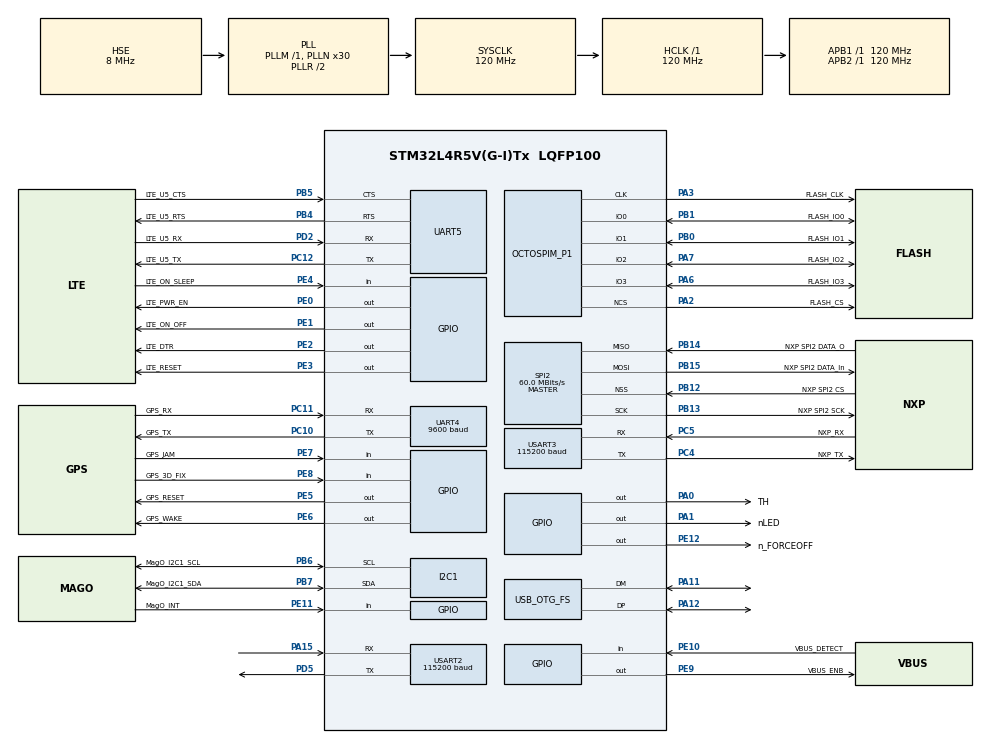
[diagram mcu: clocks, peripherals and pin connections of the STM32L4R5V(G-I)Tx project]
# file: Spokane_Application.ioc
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Dma.OCTOSPI1.10.Direction=DMA_PERIPH_TO_MEMORY
Dma.OCTOSPI1.10.EventEnable=DISABLE
Dma.OCTOSPI1.10.Instance=DMA2_Channel4
Dma.OCTOSPI1.10.MemDataAlignment=DMA_MDATAALIGN_BYTE
Dma.OCTOSPI1.10.MemInc=DMA_MINC_ENABLE
Dma.OCTOSPI1.10.Mode=DMA_NORMAL
Dma.OCTOSPI1.10.PeriphDataAlignment=DMA_PDATAALIGN_BYTE
Dma.OCTOSPI1.10.PeriphInc=DMA_PINC_DISABLE
Dma.OCTOSPI1.10.Polarity=HAL_DMAMUX_REQUEST_GEN_RISING
Dma.OCTOSPI1.10.Priority=DMA_PRIORITY_LOW
Dma.OCTOSPI1.10.RequestNumber=1
Dma.OCTOSPI1.10.SignalID=NONE
Dma.OCTOSPI1.10.SyncEnable=DISABLE
Dma.OCTOSPI1.10.SyncPolarity=HAL_DMAMUX_SYNC_NO_EVENT
Dma.OCTOSPI1.10.SyncRequestNumber=1
Dma.OCTOSPI1.10.SyncSignalID=NONE
Dma.Request0=SPI2_RX
Dma.Request1=SPI2_TX
Dma.Request10=OCTOSPI1
Dma.Request2=UART5_RX
Dma.Request3=UART5_TX
Dma.Request4=USART3_RX
Dma.Request5=USART3_TX
Dma.Request6=USART2_TX
Dma.Request7=USART2_RX
Dma.Request8=UART4_TX
Dma.Request9=UART4_RX
Dma.SPI2_RX.0.Direction=DMA_PERIPH_TO_MEMORY
Dma.SPI2_RX.0.EventEnable=DISABLE
Dma.SPI2_RX.0.Instance=DMA1_Channel5
Dma.SPI2_RX.0.MemDataAlignment=DMA_MDATAALIGN_BYTE
Dma.SPI2_RX.0.MemInc=DMA_MINC_ENABLE
Dma.SPI2_RX.0.Mode=DMA_CIRCULAR
Dma.SPI2_RX.0.PeriphDataAlignment=DMA_PDATAALIGN_BYTE
Dma.SPI2_RX.0.PeriphInc=DMA_PINC_DISABLE
Dma.SPI2_RX.0.Polarity=HAL_DMAMUX_REQUEST_GEN_RISING
Dma.SPI2_RX.0.Priority=DMA_PRIORITY_VERY_HIGH
Dma.SPI2_RX.0.RequestNumber=1
Dma.SPI2_RX.0.SignalID=NONE
Dma.SPI2_RX.0.SyncEnable=DISABLE
Dma.SPI2_RX.0.SyncPolarity=HAL_DMAMUX_SYNC_NO_EVENT
Dma.SPI2_RX.0.SyncRequestNumber=1
Dma.SPI2_RX.0.SyncSignalID=NONE
Dma.SPI2_TX.1.Direction=DMA_MEMORY_TO_PERIPH
Dma.SPI2_TX.1.EventEnable=DISABLE
Dma.SPI2_TX.1.Instance=DMA1_Channel6
Dma.SPI2_TX.1.MemDataAlignment=DMA_MDATAALIGN_BYTE
Dma.SPI2_TX.1.MemInc=DMA_MINC_ENABLE
Dma.SPI2_TX.1.Mode=DMA_NORMAL
Dma.SPI2_TX.1.PeriphDataAlignment=DMA_PDATAALIGN_BYTE
Dma.SPI2_TX.1.PeriphInc=DMA_PINC_DISABLE
Dma.SPI2_TX.1.Polarity=HAL_DMAMUX_REQUEST_GEN_RISING
Dma.SPI2_TX.1.Priority=DMA_PRIORITY_VERY_HIGH
Dma.SPI2_TX.1.RequestNumber=1
Dma.SPI2_TX.1.SignalID=NONE
Dma.SPI2_TX.1.SyncEnable=DISABLE
Dma.SPI2_TX.1.SyncPolarity=HAL_DMAMUX_SYNC_NO_EVENT
Dma.SPI2_TX.1.SyncRequestNumber=1
Dma.SPI2_TX.1.SyncSignalID=NONE
Dma.UART4_RX.9.Direction=DMA_PERIPH_TO_MEMORY
Dma.UART4_RX.9.EventEnable=DISABLE
Dma.UART4_RX.9.Instance=DMA2_Channel3
Dma.UART4_RX.9.MemDataAlignment=DMA_MDATAALIGN_BYTE
Dma.UART4_RX.9.MemInc=DMA_MINC_ENABLE
Dma.UART4_RX.9.Mode=DMA_CIRCULAR
Dma.UART4_RX.9.PeriphDataAlignment=DMA_PDATAALIGN_BYTE
Dma.UART4_RX.9.PeriphInc=DMA_PINC_DISABLE
Dma.UART4_RX.9.Polarity=HAL_DMAMUX_REQUEST_GEN_RISING
Dma.UART4_RX.9.Priority=DMA_PRIORITY_LOW
Dma.UART4_RX.9.RequestNumber=1
Dma.UART4_RX.9.SignalID=NONE
Dma.UART4_RX.9.SyncEnable=DISABLE
Dma.UART4_RX.9.SyncPolarity=HAL_DMAMUX_SYNC_NO_EVENT
Dma.UART4_RX.9.SyncRequestNumber=1
Dma.UART4_RX.9.SyncSignalID=NONE
Dma.UART4_TX.8.Direction=DMA_MEMORY_TO_PERIPH
Dma.UART4_TX.8.EventEnable=DISABLE
Dma.UART4_TX.8.Instance=DMA2_Channel2
Dma.UART4_TX.8.MemDataAlignment=DMA_MDATAALIGN_BYTE
Dma.UART4_TX.8.MemInc=DMA_MINC_ENABLE
Dma.UART4_TX.8.Mode=DMA_NORMAL
Dma.UART4_TX.8.PeriphDataAlignment=DMA_PDATAALIGN_BYTE
Dma.UART4_TX.8.PeriphInc=DMA_PINC_DISABLE
Dma.UART4_TX.8.Polarity=HAL_DMAMUX_REQUEST_GEN_RISING
Dma.UART4_TX.8.Priority=DMA_PRIORITY_LOW
Dma.UART4_TX.8.RequestNumber=1
Dma.UART4_TX.8.SignalID=NONE
Dma.UART4_TX.8.SyncEnable=DISABLE
Dma.UART4_TX.8.SyncPolarity=HAL_DMAMUX_SYNC_NO_EVENT
Dma.UART4_TX.8.SyncRequestNumber=1
Dma.UART4_TX.8.SyncSignalID=NONE
Dma.UART5_RX.2.Direction=DMA_PERIPH_TO_MEMORY
Dma.UART5_RX.2.EventEnable=DISABLE
Dma.UART5_RX.2.Instance=DMA1_Channel1
Dma.UART5_RX.2.MemDataAlignment=DMA_MDATAALIGN_BYTE
Dma.UART5_RX.2.MemInc=DMA_MINC_ENABLE
Dma.UART5_RX.2.Mode=DMA_CIRCULAR
Dma.UART5_RX.2.PeriphDataAlignment=DMA_PDATAALIGN_BYTE
Dma.UART5_RX.2.PeriphInc=DMA_PINC_DISABLE
Dma.UART5_RX.2.Polarity=HAL_DMAMUX_REQUEST_GEN_RISING
Dma.UART5_RX.2.Priority=DMA_PRIORITY_LOW
Dma.UART5_RX.2.RequestNumber=1
Dma.UART5_RX.2.SignalID=NONE
Dma.UART5_RX.2.SyncEnable=DISABLE
Dma.UART5_RX.2.SyncPolarity=HAL_DMAMUX_SYNC_NO_EVENT
Dma.UART5_RX.2.SyncRequestNumber=1
Dma.UART5_RX.2.SyncSignalID=NONE
Dma.UART5_TX.3.Direction=DMA_MEMORY_TO_PERIPH
Dma.UART5_TX.3.EventEnable=DISABLE
Dma.UART5_TX.3.Instance=DMA1_Channel2
Dma.UART5_TX.3.MemDataAlignment=DMA_MDATAALIGN_BYTE
Dma.UART5_TX.3.MemInc=DMA_MINC_ENABLE
Dma.UART5_TX.3.Mode=DMA_NORMAL
Dma.UART5_TX.3.PeriphDataAlignment=DMA_PDATAALIGN_BYTE
Dma.UART5_TX.3.PeriphInc=DMA_PINC_DISABLE
Dma.UART5_TX.3.Polarity=HAL_DMAMUX_REQUEST_GEN_RISING
Dma.UART5_TX.3.Priority=DMA_PRIORITY_LOW
Dma.UART5_TX.3.RequestNumber=1
Dma.UART5_TX.3.SignalID=NONE
Dma.UART5_TX.3.SyncEnable=DISABLE
Dma.UART5_TX.3.SyncPolarity=HAL_DMAMUX_SYNC_NO_EVENT
Dma.UART5_TX.3.SyncRequestNumber=1
Dma.UART5_TX.3.SyncSignalID=NONE
Dma.USART2_RX.7.Direction=DMA_PERIPH_TO_MEMORY
Dma.USART2_RX.7.EventEnable=DISABLE
Dma.USART2_RX.7.Instance=DMA2_Channel1
Dma.USART2_RX.7.MemDataAlignment=DMA_MDATAALIGN_BYTE
Dma.USART2_RX.7.MemInc=DMA_MINC_ENABLE
Dma.USART2_RX.7.Mode=DMA_CIRCULAR
Dma.USART2_RX.7.PeriphDataAlignment=DMA_PDATAALIGN_BYTE
Dma.USART2_RX.7.PeriphInc=DMA_PINC_DISABLE
Dma.USART2_RX.7.Polarity=HAL_DMAMUX_REQUEST_GEN_RISING
Dma.USART2_RX.7.Priority=DMA_PRIORITY_LOW
Dma.USART2_RX.7.RequestNumber=1
Dma.USART2_RX.7.SignalID=NONE
Dma.USART2_RX.7.SyncEnable=DISABLE
Dma.USART2_RX.7.SyncPolarity=HAL_DMAMUX_SYNC_NO_EVENT
Dma.USART2_RX.7.SyncRequestNumber=1
Dma.USART2_RX.7.SyncSignalID=NONE
Dma.USART2_TX.6.Direction=DMA_MEMORY_TO_PERIPH
Dma.USART2_TX.6.EventEnable=DISABLE
Dma.USART2_TX.6.Instance=DMA1_Channel7
Dma.USART2_TX.6.MemDataAlignment=DMA_MDATAALIGN_BYTE
Dma.USART2_TX.6.MemInc=DMA_MINC_ENABLE
Dma.USART2_TX.6.Mode=DMA_NORMAL
Dma.USART2_TX.6.PeriphDataAlignment=DMA_PDATAALIGN_BYTE
Dma.USART2_TX.6.PeriphInc=DMA_PINC_DISABLE
Dma.USART2_TX.6.Polarity=HAL_DMAMUX_REQUEST_GEN_RISING
Dma.USART2_TX.6.Priority=DMA_PRIORITY_LOW
Dma.USART2_TX.6.RequestNumber=1
Dma.USART2_TX.6.SignalID=NONE
Dma.USART2_TX.6.SyncEnable=DISABLE
Dma.USART2_TX.6.SyncPolarity=HAL_DMAMUX_SYNC_NO_EVENT
Dma.USART2_TX.6.SyncRequestNumber=1
Dma.USART2_TX.6.SyncSignalID=NONE
Dma.USART3_RX.4.Direction=DMA_PERIPH_TO_MEMORY
Dma.USART3_RX.4.EventEnable=DISABLE
Dma.USART3_RX.4.Instance=DMA1_Channel3
Dma.USART3_RX.4.MemDataAlignment=DMA_MDATAALIGN_BYTE
Dma.USART3_RX.4.MemInc=DMA_MINC_ENABLE
Dma.USART3_RX.4.Mode=DMA_CIRCULAR
Dma.USART3_RX.4.PeriphDataAlignment=DMA_PDATAALIGN_BYTE
Dma.USART3_RX.4.PeriphInc=DMA_PINC_DISABLE
Dma.USART3_RX.4.Polarity=HAL_DMAMUX_REQUEST_GEN_RISING
Dma.USART3_RX.4.Priority=DMA_PRIORITY_LOW
Dma.USART3_RX.4.RequestNumber=1
Dma.USART3_RX.4.SignalID=NONE
Dma.USART3_RX.4.SyncEnable=DISABLE
Dma.USART3_RX.4.SyncPolarity=HAL_DMAMUX_SYNC_NO_EVENT
Dma.USART3_RX.4.SyncRequestNumber=1
Dma.USART3_RX.4.SyncSignalID=NONE
Dma.USART3_TX.5.Direction=DMA_MEMORY_TO_PERIPH
Dma.USART3_TX.5.EventEnable=DISABLE
Dma.USART3_TX.5.Instance=DMA1_Channel4
Dma.USART3_TX.5.MemDataAlignment=DMA_MDATAALIGN_BYTE
Dma.USART3_TX.5.MemInc=DMA_MINC_ENABLE
Dma.USART3_TX.5.Mode=DMA_NORMAL
Dma.USART3_TX.5.PeriphDataAlignment=DMA_PDATAALIGN_BYTE
Dma.USART3_TX.5.PeriphInc=DMA_PINC_DISABLE
Dma.USART3_TX.5.Polarity=HAL_DMAMUX_REQUEST_GEN_RISING
Dma.USART3_TX.5.Priority=DMA_PRIORITY_LOW
Dma.USART3_TX.5.RequestNumber=1
Dma.USART3_TX.5.SignalID=NONE
Dma.USART3_TX.5.SyncEnable=DISABLE
Dma.USART3_TX.5.SyncPolarity=HAL_DMAMUX_SYNC_NO_EVENT
Dma.USART3_TX.5.SyncRequestNumber=1
Dma.USART3_TX.5.SyncSignalID=NONE
FATFS._FS_EXFAT=1
FATFS._FS_LOCK=7
FATFS._MAX_SS=4096
FATFS._USE_LABEL=1
FATFS._USE_LFN=1
I2C1.Timing=0x307075B1
Mcu.Family=STM32L4
Mcu.Name=STM32L4R5V(G-I)Tx
Mcu.Package=LQFP100
Mcu.UserConstants=NXP_UART_PORT_NUM,3;LTE_UART_PORT_NUM,5;GPS_UART_PORT_NUM,4;PRT_UART_PORT_NUM,2
NVIC.DMA1_Channel1_IRQn=true\:0\:0\:false\:false\:true\:false\:true\:true
NVIC.DMA1_Channel2_IRQn=true\:0\:0\:false\:false\:true\:false\:true\:true
NVIC.DMA1_Channel3_IRQn=true\:0\:0\:false\:false\:true\:false\:true\:true
NVIC.DMA1_Channel4_IRQn=true\:0\:0\:false\:false\:true\:false\:true\:true
NVIC.DMA1_Channel5_IRQn=true\:0\:0\:false\:false\:true\:false\:true\:true
NVIC.DMA1_Channel6_IRQn=true\:0\:0\:false\:false\:true\:false\:true\:true
NVIC.DMA1_Channel7_IRQn=true\:0\:0\:false\:false\:true\:false\:true\:true
NVIC.DMA2_Channel1_IRQn=true\:0\:0\:false\:false\:true\:false\:true\:true
NVIC.DMA2_Channel2_IRQn=true\:0\:0\:false\:false\:true\:false\:true\:true
NVIC.DMA2_Channel3_IRQn=true\:0\:0\:false\:false\:true\:false\:true\:true
NVIC.DMA2_Channel4_IRQn=true\:0\:0\:false\:false\:true\:false\:true\:true
NVIC.OCTOSPI1_IRQn=true\:0\:0\:false\:false\:true\:true\:true\:true
NVIC.OTG_FS_IRQn=true\:0\:0\:false\:false\:true\:true\:true\:true
NVIC.PriorityGroup=NVIC_PRIORITYGROUP_4
NVIC.SPI2_IRQn=true\:0\:0\:false\:false\:true\:true\:true\:true
NVIC.UART4_IRQn=true\:0\:0\:false\:false\:true\:true\:true\:true
NVIC.UART5_IRQn=true\:0\:0\:false\:false\:true\:true\:true\:true
NVIC.USART2_IRQn=true\:0\:0\:false\:false\:true\:true\:true\:true
NVIC.USART3_IRQn=true\:0\:0\:false\:false\:true\:true\:true\:true
OCTOSPI1.ChipSelectHighTime=3
OCTOSPI1.ClockPrescaler=60
OCTOSPI1.DelayHoldQuarterCycle=HAL_OSPI_DHQC_ENABLE
OCTOSPI1.DeviceSize=27
OCTOSPI1.MemoryType=HAL_OSPI_MEMTYPE_MICRON
OCTOSPI1.SampleShifting=HAL_OSPI_SAMPLE_SHIFTING_HALFCYCLE
PA0.GPIO_Label=TH
PA0.Signal=GPIO_Output
PA1.GPIO_Label=nLED
PA1.Signal=GPIO_Output
PA11.Mode=Host_Only
PA11.Signal=USB_OTG_FS_DM
PA12.Mode=Host_Only
PA12.Signal=USB_OTG_FS_DP
PA15\ (JTDI).Mode=Asynchronous
PA15\ (JTDI).Signal=USART2_RX
PA2.GPIO_Label=FLASH_CS
PA2.Mode=OCTOSPI1_Port1_NCS
PA2.Signal=OCTOSPIM_P1_NCS
PA3.GPIO_Label=FLASH_CLK
PA3.Mode=O1_P1_CLK
PA3.Signal=OCTOSPIM_P1_CLK
PA6.GPIO_Label=FLASH_IO3
PA6.Mode=OCTOSPI1_IOL_Port1L
PA6.Signal=OCTOSPIM_P1_IO3
PA7.GPIO_Label=FLASH_IO2
PA7.Mode=OCTOSPI1_IOL_Port1L
PA7.Signal=OCTOSPIM_P1_IO2
PB0.GPIO_Label=FLASH_IO1
PB0.Mode=OCTOSPI1_IOL_Port1L
PB0.Signal=OCTOSPIM_P1_IO1
PB1.GPIO_Label=FLASH_IO0
PB1.Mode=OCTOSPI1_IOL_Port1L
PB1.Signal=OCTOSPIM_P1_IO0
PB12.GPIO_Label=NXP SPI2 CS
PB12.Mode=NSS_Signal_Hard_Input
PB12.Signal=SPI2_NSS
PB13.GPIO_Label=NXP SPI2 SCK
PB13.Mode=Full_Duplex_Master
PB13.Signal=SPI2_SCK
PB14.GPIO_Label=NXP SPI2 DATA_O
PB14.Mode=Full_Duplex_Master
PB14.Signal=SPI2_MISO
PB15.GPIO_Label=NXP SPI2 DATA_In
PB15.Mode=Full_Duplex_Master
PB15.Signal=SPI2_MOSI
PB4\ (NJTRST).GPIO_Label=LTE_U5_RTS
PB4\ (NJTRST).Mode=CTS_RTS
PB4\ (NJTRST).Signal=UART5_RTS
PB5.GPIO_Label=LTE_U5_CTS
PB5.Mode=CTS_RTS
PB5.Signal=UART5_CTS
PB6.GPIO_Label=MagO_I2C1_SCL
PB6.Mode=I2C
PB6.Signal=I2C1_SCL
PB7.GPIO_Label=MagO_I2C1_SDA
PB7.Mode=I2C
PB7.Signal=I2C1_SDA
PC10.GPIO_Label=GPS_TX
PC10.Mode=Asynchronous
PC10.Signal=UART4_TX
PC11.GPIO_Label=GPS_RX
PC11.Mode=Asynchronous
PC11.Signal=UART4_RX
PC12.GPIO_Label=LTE_U5_TX
PC12.Mode=Asynchronous
PC12.Signal=UART5_TX
PC4.GPIO_Label=NXP_TX
PC4.Mode=Asynchronous
PC4.Signal=USART3_TX
PC5.GPIO_Label=NXP_RX
PC5.Mode=Asynchronous
PC5.Signal=USART3_RX
PD2.GPIO_Label=LTE_U5_RX
PD2.Mode=Asynchronous
PD2.Signal=UART5_RX
PD5.Mode=Asynchronous
PD5.Signal=USART2_TX
PE0.GPIO_Label=LTE_PWR_EN
PE0.Signal=GPIO_Output
PE1.GPIO_Label=LTE_ON_OFF
PE1.GPIO_ModeDefaultOutputPP=GPIO_MODE_OUTPUT_OD
PE1.GPIO_PuPd=GPIO_NOPULL
PE1.Signal=GPIO_Output
PE10.GPIO_Label=VBUS_DETECT
PE10.Signal=GPIO_Input
PE11.GPIO_Label=MagO_INT
PE11.Signal=GPIO_Input
PE12.GPIO_Label=n_FORCEOFF
PE12.PinState=GPIO_PIN_SET
PE12.Signal=GPIO_Output
PE2.GPIO_Label=LTE_DTR
PE2.GPIO_ModeDefaultOutputPP=GPIO_MODE_OUTPUT_OD
PE2.GPIO_PuPd=GPIO_NOPULL
PE2.Signal=GPIO_Output
PE3.GPIO_Label=LTE_RESET
PE3.GPIO_ModeDefaultOutputPP=GPIO_MODE_OUTPUT_OD
PE3.GPIO_PuPd=GPIO_NOPULL
PE3.Signal=GPIO_Output
PE4.GPIO_Label=LTE_ON_SLEEP
PE4.Signal=GPIO_Input
PE5.GPIO_Label=GPS_RESET
PE5.GPIO_ModeDefaultOutputPP=GPIO_MODE_OUTPUT_OD
PE5.GPIO_PuPd=GPIO_NOPULL
PE5.Signal=GPIO_Output
PE6.GPIO_Label=GPS_WAKE
PE6.Signal=GPIO_Output
PE7.GPIO_Label=GPS_JAM
PE7.Signal=GPIO_Input
PE8.GPIO_Label=GPS_3D_FIX
PE8.Signal=GPIO_Input
PE9.GPIO_Label=VBUS_ENB
PE9.Signal=GPIO_Output
PH0-OSC_IN\ (PH0).Mode=HSE-External-Oscillator
PH0-OSC_IN\ (PH0).Signal=RCC_OSC_IN
PH1-OSC_OUT\ (PH1).Mode=HSE-External-Oscillator
PH1-OSC_OUT\ (PH1).Signal=RCC_OSC_OUT
ProjectManager.HeapSize=0x2000
ProjectManager.StackSize=0x2000
ProjectManager.TargetToolchain=STM32CubeIDE
RCC.ADCFreq_Value=48000000
RCC.AHBFreq_Value=120000000
RCC.APB1Freq_Value=120000000
RCC.APB1TimFreq_Value=120000000
RCC.APB2Freq_Value=120000000
RCC.APB2TimFreq_Value=120000000
RCC.CortexFreq_Value=120000000
RCC.HCLKFreq_Value=120000000
RCC.HSE_VALUE=8000000
RCC.HSI48_VALUE=48000000
RCC.HSI_VALUE=16000000
RCC.LSE_VALUE=32768
RCC.MSI_VALUE=4000000
RCC.PLLN=30
RCC.PLLSAI1N=12
RCC.PLLSourceVirtual=RCC_PLLSOURCE_HSE
RCC.SYSCLKFreq_VALUE=120000000
RCC.SYSCLKSource=RCC_SYSCLKSOURCE_PLLCLK
RCC.USBFreq_Value=48000000
RCC.VCOOutputFreq_Value=240000000
SPI2.BaudRatePrescaler=SPI_BAUDRATEPRESCALER_2
SPI2.CalculateBaudRate=60.0 MBits/s
SPI2.DataSize=SPI_DATASIZE_8BIT
SPI2.Direction=SPI_DIRECTION_2LINES
SPI2.Mode=SPI_MODE_MASTER
SPI2.NSSPMode=SPI_NSS_PULSE_DISABLE
SPI2.VirtualNSS=VM_NSSHARD
SPI2.VirtualType=VM_MASTER
UART4.BaudRate=9600
USART2.BaudRate=115200
USART2.VirtualMode-Asynchronous=VM_ASYNC
USART3.BaudRate=115200
USART3.VirtualMode-Asynchronous=VM_ASYNC
USB_HOST.BSP.number=1
USB_HOST.USBH_HandleTypeDef=hUsbHostFS
USB_HOST.VirtualModeFS=Msc
USB_HOST0.BSP.STBoard=false
USB_HOST0.BSP.api=Unknown
USB_HOST0.BSP.instance=PE9
USB_HOST0.BSP.ip=GPIO
USB_HOST0.BSP.mode=Output
USB_HOST0.BSP.name=Drive_VBUS_FS
USB_HOST0.BSP.solution=PE9
USB_OTG_FS.VirtualMode=Host_Only
USB_OTG_FS.phy_itface=HCD_PHY_EMBEDDED
VP_FATFS_VS_USB.Mode=USB
VP_OCTOSPI1_VS_quad.Mode=quad_mode
VP_USB_HOST_VS_USB_HOST_MSC_FS.Mode=MSC_FS
board=custom

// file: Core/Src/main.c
/* USER CODE BEGIN Header */
/**
  ******************************************************************************
  * @file           : main.c
  * @brief          : Main program body
  ******************************************************************************
  * @attention
  *
  * Copyright (c) 2024 STMicroelectronics.
  * All rights reserved.
  *
  * This software is licensed under terms that can be found in the LICENSE file
  * in the root directory of this software component.
  * If no LICENSE file comes with this software, it is provided AS-IS.
  *
  ******************************************************************************
  */
/* USER CODE END Header */
#include "main.h"
#include "dma.h"
#include "fatfs.h"
#include "i2c.h"
#include "octospi.h"
#include "spi.h"
#include "usart.h"
#include "usb_host.h"
#include "gpio.h"

/* USER CODE BEGIN Includes */
#include <stdio.h>
#include "Scheduler/Scheduler.h"
#include "Debug_Port.h"

/* USER CODE END Includes */

void SystemClock_Config(void);
void MX_USB_HOST_Process(void);

int main(void)
{

  /* MCU Configuration--------------------------------------------------------*/

  /* Reset of all peripherals, Initializes the Flash interface and the Systick. */
  HAL_Init();

  /* Configure the system clock */
  SystemClock_Config();

  /* Initialize all configured peripherals */
  MX_GPIO_Init();
  MX_DMA_Init();
  MX_USART3_UART_Init();
  MX_SPI2_Init();
  MX_I2C1_Init();
  MX_OCTOSPI1_Init();
  MX_UART4_Init();
  MX_UART5_Init();
  MX_USART2_UART_Init();
  MX_FATFS_Init();
  MX_USB_HOST_Init();
  /* USER CODE BEGIN 2 */
  //HAL_GPIO_WritePin(FLASH_CS_GPIO_Port, FLASH_CS_Pin, GPIO_PIN_SET);
 // HAL_Delay(3000);
  Start_Scheduler();
  Debug_Task();

  /* USER CODE END 2 */

  /* Infinite loop */
  while (1)
  {
    MX_USB_HOST_Process();

    /* USER CODE BEGIN 3 */
	  Run_Scheduler_Tasks();

  }
  /* USER CODE END 3 */
}

void SystemClock_Config(void)
{
  RCC_OscInitTypeDef RCC_OscInitStruct = {0};
  RCC_ClkInitTypeDef RCC_ClkInitStruct = {0};

  /** Configure the main internal regulator output voltage
  */
  if (HAL_PWREx_ControlVoltageScaling(PWR_REGULATOR_VOLTAGE_SCALE1_BOOST) != HAL_OK)
  {
    Error_Handler();
  }

  /** Initializes the RCC Oscillators according to the specified parameters
  * in the RCC_OscInitTypeDef structure.
  */
  RCC_OscInitStruct.OscillatorType = RCC_OSCILLATORTYPE_HSE;
  RCC_OscInitStruct.HSEState = RCC_HSE_ON;
  RCC_OscInitStruct.PLL.PLLState = RCC_PLL_ON;
  RCC_OscInitStruct.PLL.PLLSource = RCC_PLLSOURCE_HSE;
  RCC_OscInitStruct.PLL.PLLM = 1;
  RCC_OscInitStruct.PLL.PLLN = 30;
  RCC_OscInitStruct.PLL.PLLP = RCC_PLLP_DIV2;
  RCC_OscInitStruct.PLL.PLLQ = RCC_PLLQ_DIV2;
  RCC_OscInitStruct.PLL.PLLR = RCC_PLLR_DIV2;
  if (HAL_RCC_OscConfig(&RCC_OscInitStruct) != HAL_OK)
  {
    Error_Handler();
  }

  /** Initializes the CPU, AHB and APB buses clocks
  */
  RCC_ClkInitStruct.ClockType = RCC_CLOCKTYPE_HCLK|RCC_CLOCKTYPE_SYSCLK
                              |RCC_CLOCKTYPE_PCLK1|RCC_CLOCKTYPE_PCLK2;
  RCC_ClkInitStruct.SYSCLKSource = RCC_SYSCLKSOURCE_PLLCLK;
  RCC_ClkInitStruct.AHBCLKDivider = RCC_SYSCLK_DIV1;
  RCC_ClkInitStruct.APB1CLKDivider = RCC_HCLK_DIV1;
  RCC_ClkInitStruct.APB2CLKDivider = RCC_HCLK_DIV1;

  if (HAL_RCC_ClockConfig(&RCC_ClkInitStruct, FLASH_LATENCY_5) != HAL_OK)
  {
    Error_Handler();
  }
}

void Error_Handler(void)
{
  __disable_irq();
  while (1)
  {
  }
}
